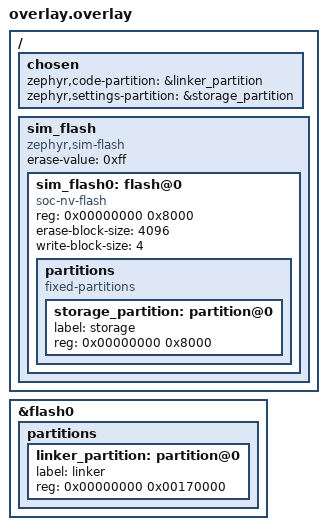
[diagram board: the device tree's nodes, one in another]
/delete-node/ &storage_partition;

/ {
	chosen {
		zephyr,code-partition = &linker_partition;
		zephyr,settings-partition = &storage_partition;
	};

	sim_flash: sim_flash {
		compatible = "zephyr,sim-flash";
		erase-value = <0xff>;
		#address-cells = <1>;
		#size-cells = <1>;

		sim_flash0: flash@0 {
			status = "okay";
			compatible = "soc-nv-flash";
			reg = <0x00000000 0x8000>;
			ranges = <0x0 0x0 0x8000>;
			erase-block-size = <4096>;
			write-block-size = <4>;
			#address-cells = <1>;
			#size-cells = <1>;

			partitions {
				compatible = "fixed-partitions";
				#address-cells = <1>;
				#size-cells = <1>;

				storage_partition: partition@0 {
					label = "storage";
					reg = <0x00000000 0x8000>;
				};
			};
		};
	};
};

&flash0 {
	partitions {
		linker_partition: partition@0 {
			label = "linker";
			reg = <0x00000000 0x00170000>;
		};
	};
};
